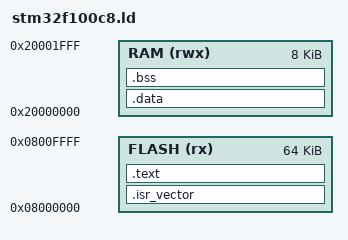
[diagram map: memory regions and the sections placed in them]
MEMORY
{
    FLASH (rx) : ORIGIN = 0x08000000, LENGTH = 64K
    RAM (rwx)  : ORIGIN = 0x20000000, LENGTH = 8K
}

_estack = ORIGIN(RAM) + LENGTH(RAM);

SECTIONS
{
    .isr_vector :
    {
        KEEP(*(.isr_vector))
    } > FLASH

    .text :
    {
        *(.text*)
        *(.rodata*)
        *(.glue_7)
        *(.glue_7t)
        *(.eh_frame*)
        . = ALIGN(4);
        _etext = .;
    } > FLASH

    _sidata = _etext;

    .data : AT(_etext)
    {
        . = ALIGN(4);
        _sdata = .;
        *(.data*)
        . = ALIGN(4);
        _edata = .;
    } > RAM

    .bss :
    {
        . = ALIGN(4);
        _sbss = .;
        *(.bss*)
        *(COMMON)
        . = ALIGN(4);
        _ebss = .;
    } > RAM

    . = ALIGN(4);
    end = .;
}
